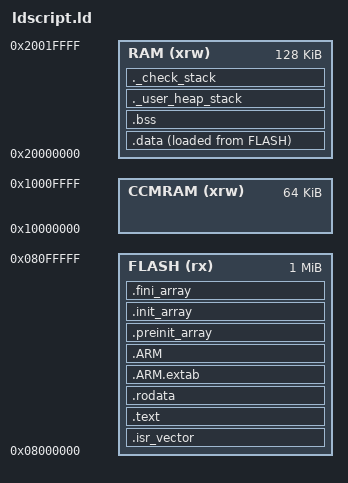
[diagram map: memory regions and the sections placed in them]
/**
 ******************************************************************************
 * @file      LinkerScript.ld
 * @author    Auto-generated by STM32CubeIDE
 * @brief     Linker script for STM32F405RGTx Device from STM32F4 series
 *                      1024Kbytes FLASH
 *                      64Kbytes CCMRAM
 *                      128Kbytes RAM
 *
 *            Set heap size, stack size and stack location according
 *            to application requirements.
 *
 *            Set memory bank area and size if external memory is used
 ******************************************************************************
 * @attention
 *
 * <h2><center>&copy; Copyright (c) 2020 STMicroelectronics.
 * All rights reserved.</center></h2>
 *
 * This software component is licensed by ST under BSD 3-Clause license,
 * the "License"; You may not use this file except in compliance with the
 * License. You may obtain a copy of the License at:
 *                        opensource.org/licenses/BSD-3-Clause
 *
 ******************************************************************************
 */

/* Entry Point */
ENTRY(Reset_Handler)

/*
 * The '__stack' definition is required by crt0, do not remove it.
 */
__stack = ORIGIN(RAM) + LENGTH(RAM);

/* Highest address of the user mode stack */
_estack = __stack;	/* end of "RAM" Ram type memory */

/*
 * Default stack sizes.
 * These are used by the startup in order to allocate stacks 
 * for the different modes.
 */

__Main_Stack_Size = 0x400 ;

PROVIDE ( _Main_Stack_Size = __Main_Stack_Size ) ;

__Main_Stack_Limit = __stack  - __Main_Stack_Size ;

/* "PROVIDE" allows to easily override these values from an 
 * object file or the command line. */
PROVIDE ( _Main_Stack_Limit = __Main_Stack_Limit ) ;

/*
 * There will be a link error if there is not this amount of 
 * RAM free at the end. 
 */
_Minimum_Stack_Size = 0x200 ;

/*
 * Default heap definitions.
 * The heap start immediately after the last statically allocated 
 * .sbss/.noinit section, and extends up to the main stack limit.
 */
PROVIDE ( _Heap_Begin = _end_noinit ) ;
PROVIDE ( _Heap_Limit = __stack - __Main_Stack_Size ) ;

/* 
 * The entry point is informative, for debuggers and simulators,
 * since the Cortex-M vector points to it anyway.
 */
ENTRY(_start)


_Min_Heap_Size = _Minimum_Stack_Size ;	/* required amount of heap  */
_Min_Stack_Size = __Main_Stack_Size ;	/* required amount of stack */

/* Memories definition */
MEMORY
{
  CCMRAM    (xrw)    : ORIGIN = 0x10000000,   LENGTH = 64K
  RAM    (xrw)    : ORIGIN = 0x20000000,   LENGTH = 128K
  FLASH    (rx)    : ORIGIN = 0x8000000,   LENGTH = 1024K
}

/* Sections */
SECTIONS
{
  /* The startup code into "FLASH" Rom type memory */
  .isr_vector :
  {
    . = ALIGN(4);
    KEEP(*(.isr_vector)) /* Startup code */
    . = ALIGN(4);
  } >FLASH

  /* The program code and other data into "FLASH" Rom type memory */
  .text :
  {
    . = ALIGN(4);
    *(.text)           /* .text sections (code) */
    *(.text*)          /* .text* sections (code) */
    *(.glue_7)         /* glue arm to thumb code */
    *(.glue_7t)        /* glue thumb to arm code */
    *(.eh_frame)

    KEEP (*(.init))
    KEEP (*(.fini))

    . = ALIGN(4);
    _etext = .;        /* define a global symbols at end of code */
  } >FLASH

  /* Constant data into "FLASH" Rom type memory */
  .rodata :
  {
    . = ALIGN(4);
    *(.rodata)         /* .rodata sections (constants, strings, etc.) */
    *(.rodata*)        /* .rodata* sections (constants, strings, etc.) */
    . = ALIGN(4);
  } >FLASH

  .ARM.extab   : { 
    . = ALIGN(4);
    *(.ARM.extab* .gnu.linkonce.armextab.*)
    . = ALIGN(4);
  } >FLASH
  
  .ARM : {
    . = ALIGN(4);
    __exidx_start = .;
    *(.ARM.exidx*)
    __exidx_end = .;
    . = ALIGN(4);
  } >FLASH

  .preinit_array     :
  {
    . = ALIGN(4);
    PROVIDE_HIDDEN (__preinit_array_start = .);
    KEEP (*(.preinit_array*))
    PROVIDE_HIDDEN (__preinit_array_end = .);
    . = ALIGN(4);
  } >FLASH
  
  .init_array :
  {
    . = ALIGN(4);
    PROVIDE_HIDDEN (__init_array_start = .);
    KEEP (*(SORT(.init_array.*)))
    KEEP (*(.init_array*))
    PROVIDE_HIDDEN (__init_array_end = .);
    . = ALIGN(4);
  } >FLASH
  
  .fini_array :
  {
    . = ALIGN(4);
    PROVIDE_HIDDEN (__fini_array_start = .);
    KEEP (*(SORT(.fini_array.*)))
    KEEP (*(.fini_array*))
    PROVIDE_HIDDEN (__fini_array_end = .);
    . = ALIGN(4);
  } >FLASH

  /* Used by the startup to initialize data */
  _sidata = LOADADDR(.data);

  /* Initialized data sections into "RAM" Ram type memory */
  .data : 
  {
    . = ALIGN(4);
    _sdata = .;        /* create a global symbol at data start */
    *(.data)           /* .data sections */
    *(.data*)          /* .data* sections */

    . = ALIGN(4);
    _edata = .;        /* define a global symbol at data end */
    
  } >RAM AT> FLASH

  /* Uninitialized data section into "RAM" Ram type memory */
  . = ALIGN(4);
  .bss :
  {
    /* This is used by the startup in order to initialize the .bss section */
    _sbss = .;         /* define a global symbol at bss start */
    __bss_start__ = _sbss;
    *(.bss)
    *(.bss*)
    *(COMMON)

    . = ALIGN(4);
    _ebss = .;         /* define a global symbol at bss end */
    __bss_end__ = _ebss;
  } >RAM

  /* User_heap_stack section, used to check that there is enough "RAM" Ram  type memory left */
  ._user_heap_stack :
  {
    . = ALIGN(8);
    PROVIDE ( end = . );
    PROVIDE ( _end = . );
    . = . + _Min_Heap_Size;
    . = . + _Min_Stack_Size;
    . = ALIGN(8);
    _end_noinit = .;
  } >RAM

    /* Mandatory to be word aligned, _sbrk assumes this */
    PROVIDE ( end = _end_noinit ); /* was _ebss */
    PROVIDE ( _end = _end_noinit );
    PROVIDE ( __end = _end_noinit );
    PROVIDE ( __end__ = _end_noinit );
    
    /*
     * Used for validation only, do not allocate anything here!
     *
     * This is just to check that there is enough RAM left for the Main
     * stack. It should generate an error if it's full.
     */
    ._check_stack : ALIGN(4)
    {
        . = . + _Minimum_Stack_Size ;
    } >RAM

  /* Remove information from the compiler libraries */
  /DISCARD/ :
  {
    libc.a ( * )
    libm.a ( * )
    libgcc.a ( * )
  }

  .ARM.attributes 0 : { *(.ARM.attributes) }

  /* Stabs debugging sections.  */
    .stab          0 : { *(.stab) }
    .stabstr       0 : { *(.stabstr) }
    .stab.excl     0 : { *(.stab.excl) }
    .stab.exclstr  0 : { *(.stab.exclstr) }
    .stab.index    0 : { *(.stab.index) }
    .stab.indexstr 0 : { *(.stab.indexstr) }
    .comment       0 : { *(.comment) }
    /*
     * DWARF debug sections.
     * Symbols in the DWARF debugging sections are relative to the beginning
     * of the section so we begin them at 0.  
     */
    /* DWARF 1 */
    .debug          0 : { *(.debug) }
    .line           0 : { *(.line) }
    /* GNU DWARF 1 extensions */
    .debug_srcinfo  0 : { *(.debug_srcinfo) }
    .debug_sfnames  0 : { *(.debug_sfnames) }
    /* DWARF 1.1 and DWARF 2 */
    .debug_aranges  0 : { *(.debug_aranges) }
    .debug_pubnames 0 : { *(.debug_pubnames) }
    /* DWARF 2 */
    .debug_info     0 : { *(.debug_info .gnu.linkonce.wi.*) }
    .debug_abbrev   0 : { *(.debug_abbrev) }
    .debug_line     0 : { *(.debug_line) }
    .debug_frame    0 : { *(.debug_frame) }
    .debug_str      0 : { *(.debug_str) }
    .debug_loc      0 : { *(.debug_loc) }
    .debug_macinfo  0 : { *(.debug_macinfo) }
    /* SGI/MIPS DWARF 2 extensions */
    .debug_weaknames 0 : { *(.debug_weaknames) }
    .debug_funcnames 0 : { *(.debug_funcnames) }
    .debug_typenames 0 : { *(.debug_typenames) }
    .debug_varnames  0 : { *(.debug_varnames) }    
    
}
